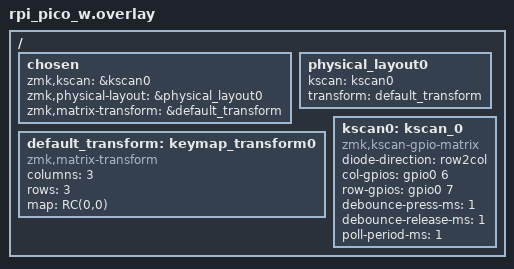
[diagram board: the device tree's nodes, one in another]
/*
Pico GPIO2  → SER (DS)
Pico GPIO3  → SRCLK
Pico GPIO5  → RCLK (同時為 CS)
OE → GND
MR → VCC
Q0 → Row 0
Q1 → Row 1
Q2 → Row 2
Q3–Q7 → 留作未來擴充
Column 0 – Column 3 → 直接接 Pico GPIO6–9
*/

// used to be ../ZMK-4x3test.overlay
// https://zmk.dev/docs/development/hardware-integration/pinctrl

#include <dt-bindings/zmk/matrix_transform.h>
// #include "ZMK-4x3test-layouts.dts"

    //&spi0

/ {
    chosen {
        zmk,kscan = &kscan0;
        zmk,physical-layout = &physical_layout0;
        zmk,matrix-transform = &default_transform;
    };

    physical_layout0 {
        kscan = <&kscan0>; // Label of the kscan node this layout uses
        transform = <&default_transform>; // Label of the matrix transform this layout uses
    };

    default_transform: keymap_transform0 {
        compatible = "zmk,matrix-transform";
        columns = <3>; // Length of the "col-gpios" array
        rows = <3>; // Length of the "row-gpios" array
        map = <
            RC(0,0) // RC(0,1) RC(0,2)
            // RC(1,0) RC(1,1) RC(1,2)
            // RC(2,0) RC(2,1) RC(2,2)
            // RC(3,0) RC(3,1) RC(3,2)
        >;
    };

    /* ---------- 鍵盤矩陣定義 ---------- */
    kscan0: kscan_0 {
        compatible = "zmk,kscan-gpio-matrix";
        diode-direction = "row2col"; // !DIODE!

        col-gpios = <&gpio0 6 GPIO_ACTIVE_HIGH>;
                    // <&gpio0 7 GPIO_ACTIVE_HIGH>,
                    // <&gpio0 8 GPIO_ACTIVE_HIGH>;
                    // <&gpio0 9 GPIO_ACTIVE_HIGH>;

        row-gpios = <&gpio0 7 GPIO_ACTIVE_HIGH>;
                    // <&shifter0 0 GPIO_ACTIVE_HIGH>,
                    // <&shifter0 1 GPIO_ACTIVE_HIGH>,
                    // <&shifter0 2 GPIO_ACTIVE_HIGH>;

        debounce-press-ms = <1>;
        debounce-release-ms = <1>;
        poll-period-ms = <1>;
    };
};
